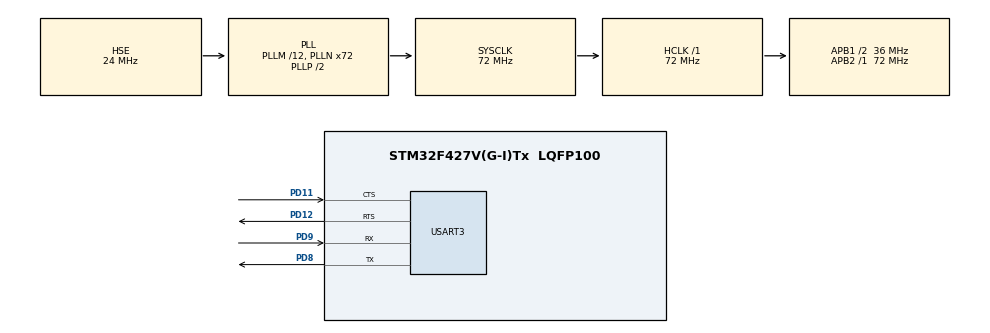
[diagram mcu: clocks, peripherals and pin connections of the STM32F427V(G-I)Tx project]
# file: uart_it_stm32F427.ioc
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Mcu.Family=STM32F4
Mcu.Name=STM32F427V(G-I)Tx
Mcu.Package=LQFP100
NVIC.PriorityGroup=NVIC_PRIORITYGROUP_4
NVIC.USART3_IRQn=true\:0\:0\:false\:false\:true\:true\:true
PA13.Mode=Serial_Wire
PA13.Signal=SYS_JTMS-SWDIO
PA14.Mode=Serial_Wire
PA14.Signal=SYS_JTCK-SWCLK
PD11.Mode=CTS_RTS
PD11.Signal=USART3_CTS
PD12.Mode=CTS_RTS
PD12.Signal=USART3_RTS
PD8.Mode=Asynchronous
PD8.Signal=USART3_TX
PD9.Mode=Asynchronous
PD9.Signal=USART3_RX
PH0/OSC_IN.Mode=HSE-External-Oscillator
PH0/OSC_IN.Signal=RCC_OSC_IN
PH1/OSC_OUT.Mode=HSE-External-Oscillator
PH1/OSC_OUT.Signal=RCC_OSC_OUT
ProjectManager.HeapSize=0x200
ProjectManager.StackSize=0x400
ProjectManager.TargetToolchain=STM32CubeIDE
RCC.48MHZClocksFreq_Value=36000000
RCC.AHBFreq_Value=72000000
RCC.APB1CLKDivider=RCC_HCLK_DIV2
RCC.APB1Freq_Value=36000000
RCC.APB1TimFreq_Value=72000000
RCC.APB2Freq_Value=72000000
RCC.APB2TimFreq_Value=72000000
RCC.CortexFreq_Value=72000000
RCC.HCLKFreq_Value=72000000
RCC.HSE_VALUE=24000000
RCC.HSI_VALUE=16000000
RCC.LSE_VALUE=32768
RCC.PLLM=12
RCC.PLLN=72
RCC.PLLSourceVirtual=RCC_PLLSOURCE_HSE
RCC.SYSCLKFreq_VALUE=72000000
RCC.SYSCLKSource=RCC_SYSCLKSOURCE_PLLCLK
RCC.VCOOutputFreq_Value=144000000
USART3.VirtualMode=VM_ASYNC
board=custom

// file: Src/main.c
/* USER CODE BEGIN Header */
/**
  ******************************************************************************
  * @file           : main.c
  * @brief          : Main program body
  ******************************************************************************
  * @attention
  *
  * <h2><center>&copy; Copyright (c) 2020 STMicroelectronics.
  * All rights reserved.</center></h2>
  *
  * This software component is licensed by ST under BSD 3-Clause license,
  * the "License"; You may not use this file except in compliance with the
  * License. You may obtain a copy of the License at:
  *                        opensource.org/licenses/BSD-3-Clause
  *
  ******************************************************************************
  */
/* USER CODE END Header */

#include "main.h"

UART_HandleTypeDef huart3;

void SystemClock_Config(void);
static void MX_GPIO_Init(void);
static void MX_USART3_UART_Init(void);
/* USER CODE BEGIN PFP */
uint8_t uart1_rxbuf[10];
/* USER CODE END PFP */

int main(void)
{

  /* MCU Configuration--------------------------------------------------------*/

  /* Reset of all peripherals, Initializes the Flash interface and the Systick. */
  HAL_Init();

  /* Configure the system clock */
  SystemClock_Config();

  /* Initialize all configured peripherals */
  MX_GPIO_Init();
  MX_USART3_UART_Init();

  /* Infinite loop */
  while (1)
  {

  }
}

void SystemClock_Config(void)
{
  RCC_OscInitTypeDef RCC_OscInitStruct = {0};
  RCC_ClkInitTypeDef RCC_ClkInitStruct = {0};

  /** Configure the main internal regulator output voltage
  */
  __HAL_RCC_PWR_CLK_ENABLE();
  __HAL_PWR_VOLTAGESCALING_CONFIG(PWR_REGULATOR_VOLTAGE_SCALE3);
  /** Initializes the CPU, AHB and APB busses clocks
  */
  RCC_OscInitStruct.OscillatorType = RCC_OSCILLATORTYPE_HSE;
  RCC_OscInitStruct.HSEState = RCC_HSE_ON;
  RCC_OscInitStruct.PLL.PLLState = RCC_PLL_ON;
  RCC_OscInitStruct.PLL.PLLSource = RCC_PLLSOURCE_HSE;
  RCC_OscInitStruct.PLL.PLLM = 12;
  RCC_OscInitStruct.PLL.PLLN = 72;
  RCC_OscInitStruct.PLL.PLLP = RCC_PLLP_DIV2;
  RCC_OscInitStruct.PLL.PLLQ = 4;
  if (HAL_RCC_OscConfig(&RCC_OscInitStruct) != HAL_OK)
  {
    Error_Handler();
  }
  /** Initializes the CPU, AHB and APB busses clocks
  */
  RCC_ClkInitStruct.ClockType = RCC_CLOCKTYPE_HCLK|RCC_CLOCKTYPE_SYSCLK
                              |RCC_CLOCKTYPE_PCLK1|RCC_CLOCKTYPE_PCLK2;
  RCC_ClkInitStruct.SYSCLKSource = RCC_SYSCLKSOURCE_PLLCLK;
  RCC_ClkInitStruct.AHBCLKDivider = RCC_SYSCLK_DIV1;
  RCC_ClkInitStruct.APB1CLKDivider = RCC_HCLK_DIV2;
  RCC_ClkInitStruct.APB2CLKDivider = RCC_HCLK_DIV1;

  if (HAL_RCC_ClockConfig(&RCC_ClkInitStruct, FLASH_LATENCY_2) != HAL_OK)
  {
    Error_Handler();
  }
}

static void MX_USART3_UART_Init(void)
{

  huart3.Instance = USART3;
  huart3.Init.BaudRate = 115200;
  huart3.Init.WordLength = UART_WORDLENGTH_8B;
  huart3.Init.StopBits = UART_STOPBITS_1;
  huart3.Init.Parity = UART_PARITY_NONE;
  huart3.Init.Mode = UART_MODE_TX_RX;
  huart3.Init.HwFlowCtl = UART_HWCONTROL_RTS_CTS;
  huart3.Init.OverSampling = UART_OVERSAMPLING_16;
  if (HAL_UART_Init(&huart3) != HAL_OK)
  {
    Error_Handler();
  }
  /* USER CODE BEGIN USART3_Init 2 */
	HAL_UART_Receive_IT(&huart3, uart1_rxbuf, 1);
  /* USER CODE END USART3_Init 2 */

}

static void MX_GPIO_Init(void)
{

  /* GPIO Ports Clock Enable */
  __HAL_RCC_GPIOH_CLK_ENABLE();
  __HAL_RCC_GPIOD_CLK_ENABLE();
  __HAL_RCC_GPIOA_CLK_ENABLE();

}

/* USER CODE BEGIN 4 */
void HAL_UART_RxCpltCallback(UART_HandleTypeDef *huart)
{
	HAL_UART_Transmit(&huart3, (uint8_t *)uart1_rxbuf, 1, 1);    // 把收到的字节原样发送出去
	HAL_UART_Receive_IT(&huart3, uart1_rxbuf, 1);       // 重新注册一次，要不然下次收不到了
}

/* USER CODE END 4 */

void Error_Handler(void)
{
}

/************************ (C) COPYRIGHT STMicroelectronics *****END OF FILE****/
